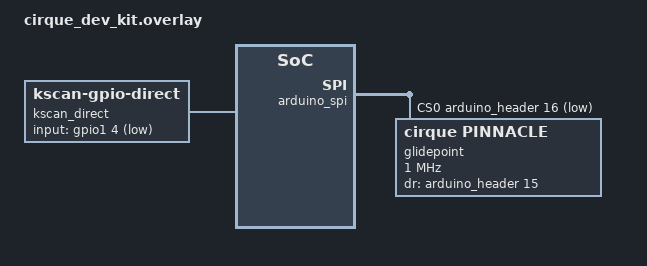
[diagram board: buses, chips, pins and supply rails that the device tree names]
#include <dt-bindings/zmk/matrix_transform.h>

/ {
	chosen {
		zmk,kscan = &kscan_direct;
		zmk,matrix-transform = &default_transform;
	};
    kscan_direct: kscan_direct {
        compatible = "zmk,kscan-gpio-direct";
        wakeup-source;

        input-gpios
        = <&gpio1 4 (GPIO_ACTIVE_LOW | GPIO_PULL_UP)>;

    };

    default_transform: keymap_transform_0 {
        compatible = "zmk,matrix-transform";
        columns = <1>;
        rows = <1>;
        map = < RC(0,0) >;
    };

    glidepoint_input {
        compatible = "zmk,input-listener";
        device = <&glidepoint>;

        xy-swap;
        y-invert;
        x-invert;
        scale-multiplier = <4> ;
    };
};

&arduino_spi {
    status = "okay";
    cs-gpios = <&arduino_header 16 GPIO_ACTIVE_LOW>;
    glidepoint: glidepoint@0 {
        compatible = "cirque,pinnacle";
        reg = <0>;
        spi-max-frequency = <1000000>;
        status = "okay";
        dr-gpios = <&arduino_header 15 (GPIO_ACTIVE_HIGH)>;

        sensitivity = "4x";
        sleep;
        no-taps;
    };
};
